# STM32L4P5 register map
File version: 1.8
CPU: CM4 r0p1, little endian, MPU, FPU, 4 interrupt priority bits
Registers are 32-bit, read-write, reset 0x0 unless marked. A register's access mark holds for its fields unless they carry their own. Offsets are from the block's base; [hi:lo] are bit positions; lines under a group give offsets from that group; {n}, {i} and the like mark numbered series.

## CRC — Cyclic redundancy check calculation unit
Base 0x40023000
0x00 DR reset 0xFFFFFFFF — Data register
  [31:0] DR — Data register bits
0x00 DR8 8-bit reset 0xFF (alternate view of DR) — Data register - byte sized
  [7:0] DR8 — Data register bits
0x00 DR16 16-bit reset 0xFFFF (alternate view of DR) — Data register - half-word sized
  [15:0] DR16 — Data register bits
0x04 IDR — Independent data register
  [7:0] IDR — General-purpose 8-bit data register bits
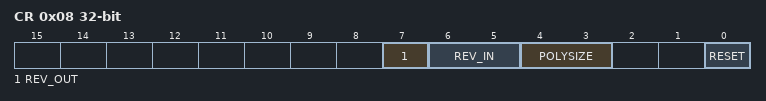
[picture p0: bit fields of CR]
0x08 CR access per field — Control register
  [7] REV_OUT rw — Reverse output data
    0=Normal (Bit order not affected); 1=Reversed (Bit reversed output)
  [6:5] REV_IN rw — Reverse input data
    0=Normal (Bit order not affected); 1=Byte (Bit reversal done by byte); 2=HalfWord (Bit reversal done by half-word); 3=Word (Bit reversal done by word)
  [4:3] POLYSIZE rw — Polynomial size
    0=32-bit polynomial; 1=16-bit polynomial; 2=8-bit polynomial; 3=7-bit polynomial
  [0] RESET wo — RESET bit
    1=Resets the CRC calculation unit and sets the data register to 0xFFFF FFFF
0x10 INIT reset 0xFFFFFFFF — Initial CRC value
  [31:0] INIT — Programmable initial CRC value
0x14 POL reset 0x4C11DB7 — polynomial
  [31:0] POL — Programmable polynomial

## TSC — Touch sensing controller
Base 0x40024000
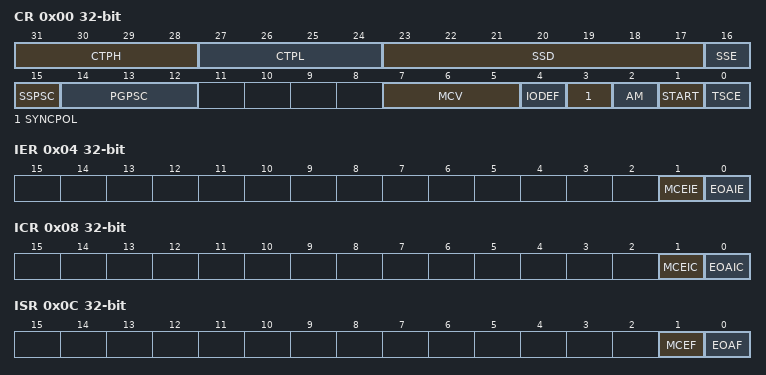
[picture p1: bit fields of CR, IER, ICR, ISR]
0x00 CR — control register
  [31:28] CTPH — Charge transfer pulse high
  [27:24] CTPL — Charge transfer pulse low
  [23:17] SSD — Spread spectrum deviation
  [16] SSE — Spread spectrum enable
    0=Disabled (Spread spectrum disabled); 1=Enabled (Spread spectrum enabled)
  [15] SSPSC — Spread spectrum prescaler
  [14:12] PGPSC — pulse generator prescaler
  [7:5] MCV — Max count value
  [4] IODEF — I/O Default mode
    0=PushPull (I/Os are forced to output push-pull low); 1=Floating (I/Os are in input floating)
  [3] SYNCPOL — Synchronization pin polarity
    0=Falling edge only; 1=Rising edge and high level
  [2] AM — Acquisition mode
    0=Normal acquisition mode (acquisition starts as soon as START bit is set); 1=Synchronized acquisition mode (acquisition starts if START bit is set and when the selected signal is detected on the SYNC input pin)
  [1] START — Start a new acquisition
    0=NoStarted (Acquisition not started); 1=Started (Start a new acquisition)
  [0] TSCE — Touch sensing controller enable
    0=Disabled (Touch sensing controller disabled); 1=Enabled (Touch sensing controller enabled)
0x04 IER — interrupt enable register
  [1] MCEIE — Max count error interrupt enable
    0=Disabled (Max count error interrupt disabled); 1=Enabled (Max count error interrupt enabled)
  [0] EOAIE — End of acquisition interrupt enable
    0=Disabled (End of acquisition interrupt disabled); 1=Enabled (End of acquisition interrupt enabled)
0x08 ICR — interrupt clear register
  [1] MCEIC — Max count error interrupt clear
  [0] EOAIC — End of acquisition interrupt clear
0x0C ISR — interrupt status register
  [1] MCEF — Max count error flag
  [0] EOAF — End of acquisition flag
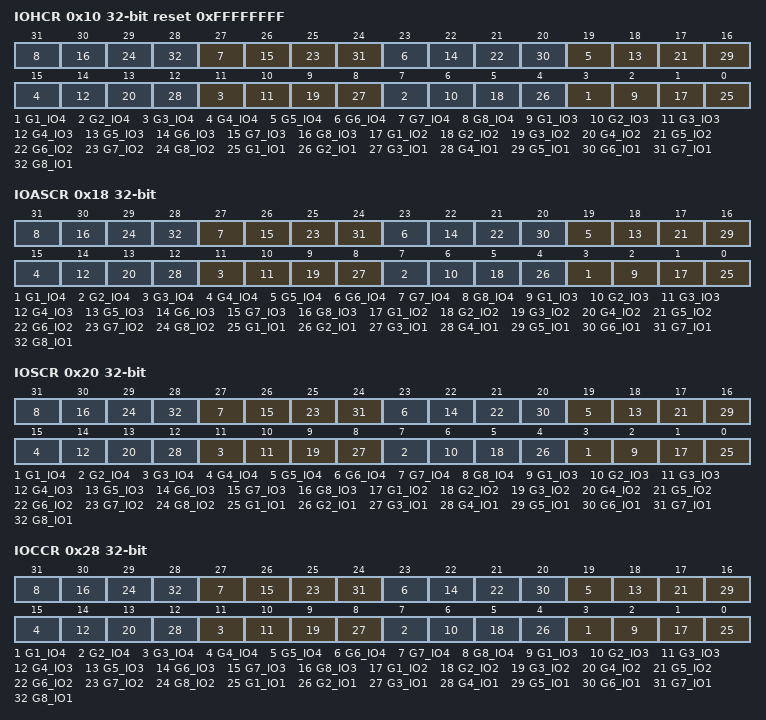
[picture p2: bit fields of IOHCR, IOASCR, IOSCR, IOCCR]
0x10 IOHCR reset 0xFFFFFFFF — I/O hysteresis control register
  [all] fields
    0=Disabled (Gx_IOy Schmitt trigger hysteresis disabled); 1=Enabled (Gx_IOy Schmitt trigger hysteresis enabled)
  [4n-1] G{n}_IO4 (n=1..8) — G{n}_IO4
  [4n-2] G{n}_IO3 (n=1..8) — G{n}_IO3
  [4n-3] G{n}_IO2 (n=1..8) — G{n}_IO2
  [4n-4] G{n}_IO1 (n=1..8) — G{n}_IO1
0x18 IOASCR — I/O analog switch control register
  [all] fields
    0=Disabled (Gx_IOy analog switch disabled (opened)); 1=Enabled (Gx_IOy analog switch enabled (closed))
  [4n-1] G{n}_IO4 (n=1..8) — G{n}_IO4
  [4n-2] G{n}_IO3 (n=1..8) — G{n}_IO3
  [4n-3] G{n}_IO2 (n=1..8) — G{n}_IO2
  [4n-4] G{n}_IO1 (n=1..8) — G{n}_IO1
0x20 IOSCR — I/O sampling control register
  [all] fields
    0=Disabled (Gx_IOy unused); 1=Enabled (Gx_IOy used as sampling capacitor)
  [4n-1] G{n}_IO4 (n=1..8) — G{n}_IO4
  [4n-2] G{n}_IO3 (n=1..8) — G{n}_IO3
  [4n-3] G{n}_IO2 (n=1..8) — G{n}_IO2
  [4n-4] G{n}_IO1 (n=1..8) — G{n}_IO1
0x28 IOCCR — I/O channel control register
  [all] fields
    0=Disabled (Gx_IOy unused); 1=Enabled (Gx_IOy used as channel)
  [4n-1] G{n}_IO4 (n=1..8) — G{n}_IO4
  [4n-2] G{n}_IO3 (n=1..8) — G{n}_IO3
  [4n-3] G{n}_IO2 (n=1..8) — G{n}_IO2
  [4n-4] G{n}_IO1 (n=1..8) — G{n}_IO1
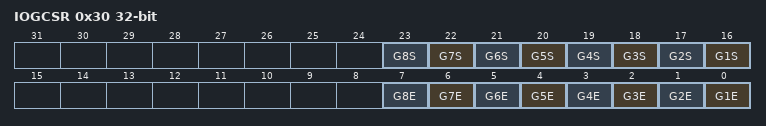
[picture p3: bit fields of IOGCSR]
0x30 IOGCSR access per field — I/O group control status register
  [n+15] G{n}S (n=1..8) ro — Analog I/O group x status
    0=Ongoing (Acquisition on analog I/O group x is ongoing or not started); 1=Complete (Acquisition on analog I/O group x is complete)
  [n-1] G{n}E (n=1..8) rw — Analog I/O group x enable
    0=Disabled (Acquisition on analog I/O group x disabled); 1=Enabled (Acquisition on analog I/O group x enabled)
{0x30+4i} IOG{i}CR (i=1..8) ro — I/O group x counter register
  [13:0] CNT — Counter value
